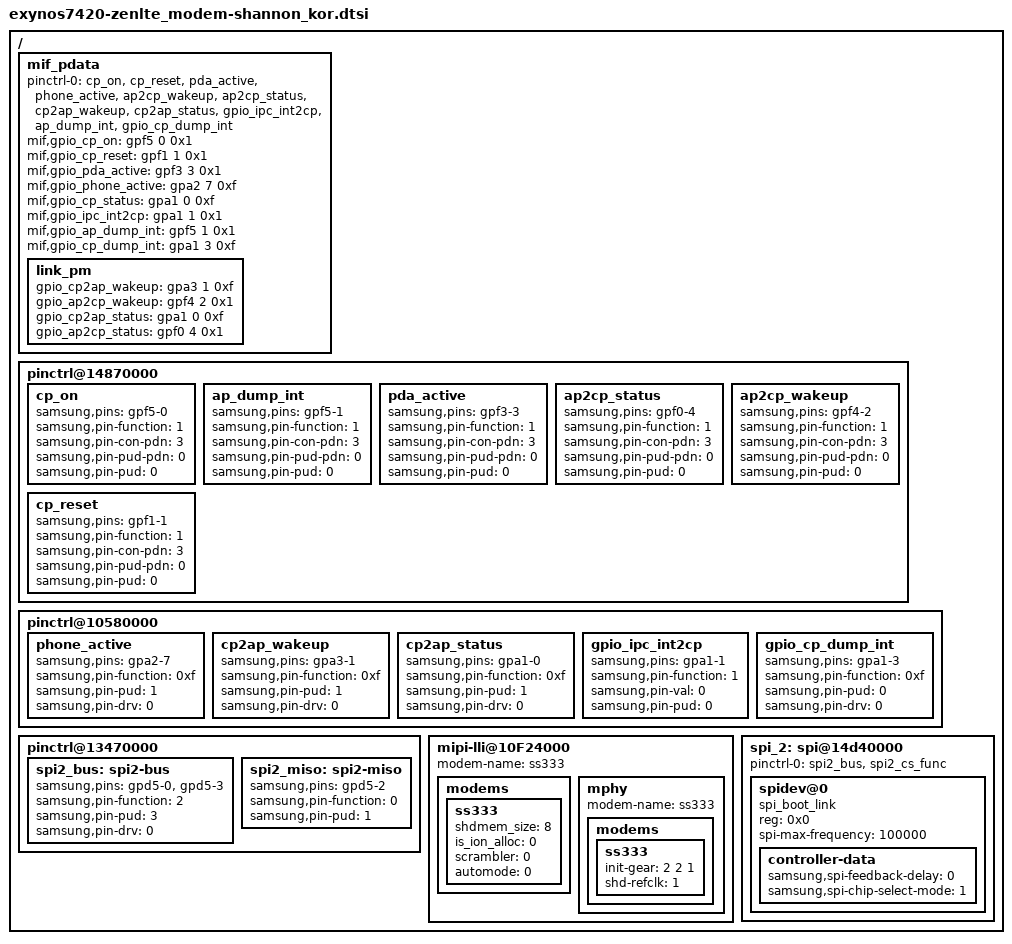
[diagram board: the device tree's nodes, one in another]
/*
 * SAMSUNG universal5422 board device tree source
 *
 * Copyright (c) 2013 Samsung Electronics Co., Ltd.
 *             http://www.samsung.com
 *
 * This program is free software; you can redistribute it and/or modify
 * it under the terms of the GNU General Public License version 2 as
 * published by the Free Software Foundation.
*/

#include "modem-ss333-kor-pdata.dtsi"

/* modem_interface_driver: UMTS modem, 2G/3G/4G, Samsung Electronics Shannon333 (SS333) */

/ {
	mif_pdata {
		status = "okay";

		pinctrl-names = "default";
		pinctrl-0 = <&cp_on &cp_reset &pda_active &phone_active &ap2cp_wakeup &ap2cp_status
							&cp2ap_wakeup &cp2ap_status &gpio_ipc_int2cp
							&ap_dump_int &gpio_cp_dump_int>;

		mif,gpio_cp_on = <&gpf5 0 0x1>;

		mif,gpio_cp_reset = <&gpf1 1 0x1>;
		mif,gpio_pda_active = <&gpf3 3 0x1>;
		mif,gpio_phone_active = <&gpa2 7 0xf>;

		mif,gpio_cp_status = <&gpa1 0 0xf>;
		mif,gpio_ipc_int2cp = <&gpa1 1 0x1>;
		mif,gpio_ap_dump_int = <&gpf5 1 0x1>;
		mif,gpio_cp_dump_int = <&gpa1 3 0xf>;

		link_pm {
			gpio_cp2ap_wakeup = <&gpa3 1 0xf>;
			gpio_ap2cp_wakeup = <&gpf4 2 0x1>;
			gpio_cp2ap_status = <&gpa1 0 0xf>;
			gpio_ap2cp_status = <&gpf0 4 0x1>;
		};
	};

	pinctrl@14870000 {
		cp_on: cp_on {
			samsung,pins = "gpf5-0";
			samsung,pin-function = <1>;
			samsung,pin-con-pdn = <3>;
			samsung,pin-pud-pdn = <0>;
			samsung,pin-pud = <0>;
		};

		ap_dump_int: ap_dump_int {
			samsung,pins = "gpf5-1";
			samsung,pin-function = <1>;
			samsung,pin-con-pdn = <3>;
			samsung,pin-pud-pdn = <0>;
			samsung,pin-pud = <0>;

		};

		pda_active: pda_active {
			samsung,pins = "gpf3-3";
			samsung,pin-function = <1>;
			samsung,pin-con-pdn = <3>;
			samsung,pin-pud-pdn = <0>;
			samsung,pin-pud = <0>;
		};

		ap2cp_status: ap2cp_status {
			samsung,pins = "gpf0-4";
			samsung,pin-function = <1>;
			samsung,pin-con-pdn = <3>;
			samsung,pin-pud-pdn = <0>;
			samsung,pin-pud = <0>;
		};

		ap2cp_wakeup: ap2cp_wakeup {
			samsung,pins = "gpf4-2";
			samsung,pin-function = <1>;
			samsung,pin-con-pdn = <3>;
			samsung,pin-pud-pdn = <0>;
			samsung,pin-pud = <0>;
		};

		cp_reset: cp_reset {
			samsung,pins = "gpf1-1";
			samsung,pin-function = <1>;
			samsung,pin-con-pdn = <3>;
			samsung,pin-pud-pdn = <0>;
			samsung,pin-pud = <0>;
		};

	};

	pinctrl@10580000 {
		phone_active: phone_active {
			samsung,pins = "gpa2-7";
			samsung,pin-function = <0xf>;
			samsung,pin-pud = <1>;
			samsung,pin-drv = <0>;
		};

		cp2ap_wakeup: cp2ap_wakeup {
			samsung,pins = "gpa3-1";
			samsung,pin-function = <0xf>;
			samsung,pin-pud = <1>;
			samsung,pin-drv = <0>;
		};

		cp2ap_status: cp2ap_status {
			samsung,pins = "gpa1-0";
			samsung,pin-function = <0xf>;
			samsung,pin-pud = <1>;
			samsung,pin-drv = <0>;
		};

		gpio_ipc_int2cp: gpio_ipc_int2cp {
			samsung,pins = "gpa1-1";
			samsung,pin-function = <1>;
			samsung,pin-val = <0>;
			samsung,pin-pud = <0>;
		};

		gpio_cp_dump_int: gpio_cp_dump_int {
			samsung,pins = "gpa1-3";
			samsung,pin-function = <0xf>;
			samsung,pin-pud = <0>;
			samsung,pin-drv = <0>;
		};
	};

	pinctrl@13470000 {
		spi2_bus: spi2-bus {
			samsung,pins = "gpd5-0", "gpd5-3";
			samsung,pin-function = <2>;
			samsung,pin-pud = <3>;
			samsung,pin-drv = <0>;
		};
		spi2_miso: spi2-miso {
			samsung,pins = "gpd5-2";
			samsung,pin-function = <0>;
			samsung,pin-pud = <1>;
		};
	};

	mipi-lli@10F24000 {
		modem-name = "ss333";

		modems {
			ss333 {
				/* shared memory size for IPC */
				shdmem_size = <8>;
				/* is the shdmem allocated by ion */
				is_ion_alloc = <0>;
				/* disable scrambler */
				scrambler = <0>;
				/* do not control automode by AP */
				automode = <0>;
			};
		};

		mphy {
			modem-name = "ss333";
			modems {
				ss333 {
					/* initial-gear is HS-G2 */
					init-gear = <2 2 1>;
					/* use shared reference clock for MPHY */
					shd-refclk = <1>;
				};
			};
		};
	};

	spi_2: spi@14d40000 {/* for modem booting */
		pinctrl-names = "default";
		pinctrl-0 = <&spi2_bus>, <&spi2_cs_func>;
		status = "okay";

		spidev@0 {
			#address-cells = <1>;
			#size-cells = <1>;
			compatible = "spi_boot_link";
			reg = <0x0>;
			spi-max-frequency = <100000>;

			controller-data {
				samsung,spi-feedback-delay = <0>;
				samsung,spi-chip-select-mode = <1>;
			};
		};
	};
};
